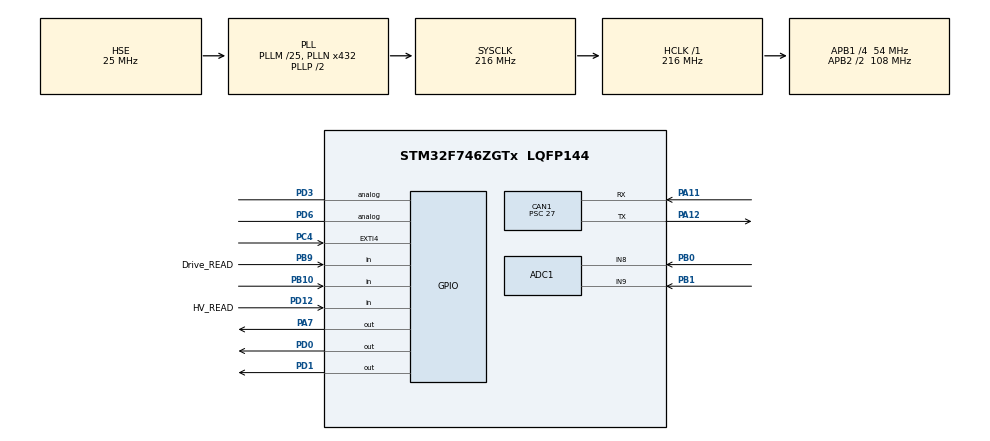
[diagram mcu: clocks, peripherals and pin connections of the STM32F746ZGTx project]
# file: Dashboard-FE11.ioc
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ADC1.Channel-0\#ChannelRegularConversion=ADC_CHANNEL_9
ADC1.NbrOfConversionFlag=1
ADC1.Rank-0\#ChannelRegularConversion=1
ADC1.SamplingTime-0\#ChannelRegularConversion=ADC_SAMPLETIME_3CYCLES
ADC1.master=1
CAN1.BS2=CAN_BS2_2TQ
CAN1.CalculateBaudRate=500000
CAN1.CalculateTimeBit=2000
CAN1.CalculateTimeQuantum=500.0
CAN1.Prescaler=27
Mcu.Family=STM32F7
Mcu.Name=STM32F746ZGTx
Mcu.Package=LQFP144
NVIC.PriorityGroup=NVIC_PRIORITYGROUP_4
PA11.Mode=CAN_Activate
PA11.Signal=CAN1_RX
PA12.Mode=CAN_Activate
PA12.Signal=CAN1_TX
PA7.Signal=GPIO_Output
PB0.Signal=ADCx_IN8
PB1.Signal=ADCx_IN9
PB10.Signal=GPIO_Input
PB11.Signal=USART3_RX
PB9.GPIO_Label=Drive_READ
PB9.Signal=GPIO_Input
PC4.Signal=GPXTI4
PD0.Signal=GPIO_Output
PD1.Signal=GPIO_Output
PD12.GPIO_Label=HV_READ
PD12.GPIO_PuPd=GPIO_PULLDOWN
PD12.Signal=GPIO_Input
PD3.Signal=GPIO_Analog
PD6.Signal=GPIO_Analog
PH0/OSC_IN.Mode=HSE-External-Oscillator
PH0/OSC_IN.Signal=RCC_OSC_IN
PH1/OSC_OUT.Mode=HSE-External-Oscillator
PH1/OSC_OUT.Signal=RCC_OSC_OUT
ProjectManager.HeapSize=0x200
ProjectManager.StackSize=0x400
ProjectManager.TargetToolchain=STM32CubeIDE
RCC.AHBFreq_Value=216000000
RCC.APB1CLKDivider=RCC_HCLK_DIV4
RCC.APB1Freq_Value=54000000
RCC.APB1TimFreq_Value=108000000
RCC.APB2CLKDivider=RCC_HCLK_DIV2
RCC.APB2Freq_Value=108000000
RCC.APB2TimFreq_Value=216000000
RCC.CortexFreq_Value=216000000
RCC.HCLKFreq_Value=216000000
RCC.HSE_VALUE=25000000
RCC.HSI_VALUE=16000000
RCC.LSE_VALUE=32768
RCC.PLLM=25
RCC.PLLN=432
RCC.PLLSourceVirtual=RCC_PLLSOURCE_HSE
RCC.SYSCLKFreq_VALUE=216000000
RCC.SYSCLKSource=RCC_SYSCLKSOURCE_PLLCLK
RCC.USBFreq_Value=216000000
RCC.VCOOutputFreq_Value=432000000
SH.ADCx_IN8.0=ADC1_IN8,IN8
SH.ADCx_IN9.0=ADC1_IN9,IN9
board=custom

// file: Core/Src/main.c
/* USER CODE BEGIN Header */
/**
  ******************************************************************************
  * @file           : main.c
  * @brief          : Main program body
  ******************************************************************************
  * @attention
  *
  * Copyright (c) 2023 STMicroelectronics.
  * All rights reserved.
  *
  * This software is licensed under terms that can be found in the LICENSE file
  * in the root directory of this software component.
  * If no LICENSE file comes with this software, it is provided AS-IS.
  *
  ******************************************************************************
  */
/* USER CODE END Header */
#include "main.h"

/* USER CODE BEGIN Includes */
#include "can_manager.h"
/* USER CODE END Includes */

ADC_HandleTypeDef hadc1;

CAN_HandleTypeDef hcan1;

/* USER CODE BEGIN PV */
uint8_t switches = 0;
uint8_t debugMode = 0;
/* USER CODE END PV */

void SystemClock_Config(void);
static void MX_GPIO_Init(void);
static void MX_CAN1_Init(void);
static void MX_ADC1_Init(void);

int main(void)
{

  /* MCU Configuration--------------------------------------------------------*/

  /* Reset of all peripherals, Initializes the Flash interface and the Systick. */
  HAL_Init();

  /* Configure the system clock */
  SystemClock_Config();

  /* Initialize all configured peripherals */
  MX_GPIO_Init();
  MX_CAN1_Init();
  MX_ADC1_Init();

  /* Infinite loop */
  while (1)
  {
	  // check driver switches
	          if (!HV_Read()) {
	              switches |= 0b10;
	          } else {
	              switches &= 0b11111101;
	          }
	          if (!Drive_Read()) {
	              switches |= 0b1;
	          } else {
	              switches &= 0b11111110;
	          }

	          if (!Digital2_Read()) {
	              if (debugMode) { // switch to drive mode
	                  debugMode = 0;
	              }
	              else { // switch to debug mode
	                  debugMode = 1;
	              }
	          }

	          if (!Digital3_Read() || !Digital4_Read()) {
	              if (switches & 0b100) { // switch to drive mode
	                 switches &= 0b11111011;
	              }
	              else { // switch to debug mode
	                  switches |= 0b100;
	              }
	          }

	          // send driver switches
	          can_send_switches(switches);

	          // this is where we actually display
	          ADC_GLV_V_StartConvert();
	          uint32_t analog_1 = (int32_t)ADC_GLV_V_CountsTo_mVolts(0, ADC_GLV_V_GetResult16(0));
	          torque_limit = analog_1 * 255/3300; // scale to 8 bit

	          //uint32_t glv_v = (int32_t)ADC_GLV_V_CountsTo_mVolts(0, ADC_GLV_V_GetResult16(1));

	          if (debugMode && prev_debugMode == 0){
	              debugTemplate();
	              clear_colors();
	              prev_debugMode = 1;
	          }
	          if (!debugMode && prev_debugMode == 1) {
	              clear_colors();
	              driveTemplate();
	              prev_debugMode = 0;
	          }

	          // big displays are usually 180 by 135
	          // small displays are usually (60-90) by 30
	          // need to adjust size of squares for changing fontSize

	          if(debugMode){
	              disp_SOC(soc, 10, 35, 240, 65, SMALL_FONT);
	              disp_max_pack_temp(PACK_TEMP, 250, 35, 470, 65, SMALL_FONT);
	              disp_state(state, 10, 100, 240, 130, SMALL_FONT);
	              disp_mc_temp(mc_temp, 250, 100, 470, 130, SMALL_FONT);
	              disp_glv_v(0, 10, 165, 240, 195, SMALL_FONT);
	              disp_motor_temp(torque_limit, 250, 165, 470, 195, SMALL_FONT);
	              disp_shutdown_circuit(shutdown_flags, 10, 230, 240, 260, SMALL_FONT);
	              //disp_debug(debug_data, 250, 230, 470, 260, SMALL_FONT);
	              disp_mc_fault(mc_fault_codes, 250, 230, 470, 260, SMALL_FONT);
	          }else{
	              disp_SOC(soc, 30, 35, 210, 170, BIG_FONT);
	              disp_max_pack_temp(PACK_TEMP, 270, 35, 450, 170, BIG_FONT);
	              disp_state(state, 20, 200, 200, 230, SMALL_FONT);
	              disp_glv_v(0, 290, 200, 470, 230, SMALL_FONT);

	          }

	          /*      END display latest data         */

	          if (state == DRIVE && previous_state == HV_ENABLED) {
	              // entered drive; sound ready to drive buzzer

	              Buzzer_Write(1);
	              // EV.10.5.2: Sounded continuously for minimum 1 second
	              // and a maximum of 3 seconds [we use 2 seconds]
	              ReadyToDrive_Timer_Start();

	          }

	          previous_state = state;
	          if (state != DRIVE) {
	              // exited drive
	              Buzzer_Write(0);
	          }

	          RGB3_1_Write(1);
	          RGB2_1_Write(1);
	          RGB1_1_Write(1);

  }
}

void SystemClock_Config(void)
{
  RCC_OscInitTypeDef RCC_OscInitStruct = {0};
  RCC_ClkInitTypeDef RCC_ClkInitStruct = {0};

  /** Configure the main internal regulator output voltage
  */
  __HAL_RCC_PWR_CLK_ENABLE();
  __HAL_PWR_VOLTAGESCALING_CONFIG(PWR_REGULATOR_VOLTAGE_SCALE1);

  /** Initializes the RCC Oscillators according to the specified parameters
  * in the RCC_OscInitTypeDef structure.
  */
  RCC_OscInitStruct.OscillatorType = RCC_OSCILLATORTYPE_HSE;
  RCC_OscInitStruct.HSEState = RCC_HSE_ON;
  RCC_OscInitStruct.PLL.PLLState = RCC_PLL_ON;
  RCC_OscInitStruct.PLL.PLLSource = RCC_PLLSOURCE_HSE;
  RCC_OscInitStruct.PLL.PLLM = 25;
  RCC_OscInitStruct.PLL.PLLN = 432;
  RCC_OscInitStruct.PLL.PLLP = RCC_PLLP_DIV2;
  RCC_OscInitStruct.PLL.PLLQ = 2;
  if (HAL_RCC_OscConfig(&RCC_OscInitStruct) != HAL_OK)
  {
    Error_Handler();
  }

  /** Activate the Over-Drive mode
  */
  if (HAL_PWREx_EnableOverDrive() != HAL_OK)
  {
    Error_Handler();
  }

  /** Initializes the CPU, AHB and APB buses clocks
  */
  RCC_ClkInitStruct.ClockType = RCC_CLOCKTYPE_HCLK|RCC_CLOCKTYPE_SYSCLK
                              |RCC_CLOCKTYPE_PCLK1|RCC_CLOCKTYPE_PCLK2;
  RCC_ClkInitStruct.SYSCLKSource = RCC_SYSCLKSOURCE_PLLCLK;
  RCC_ClkInitStruct.AHBCLKDivider = RCC_SYSCLK_DIV1;
  RCC_ClkInitStruct.APB1CLKDivider = RCC_HCLK_DIV4;
  RCC_ClkInitStruct.APB2CLKDivider = RCC_HCLK_DIV2;

  if (HAL_RCC_ClockConfig(&RCC_ClkInitStruct, FLASH_LATENCY_7) != HAL_OK)
  {
    Error_Handler();
  }
}

static void MX_ADC1_Init(void)
{

  ADC_ChannelConfTypeDef sConfig = {0};

  /** Configure the global features of the ADC (Clock, Resolution, Data Alignment and number of conversion)
  */
  hadc1.Instance = ADC1;
  hadc1.Init.ClockPrescaler = ADC_CLOCK_SYNC_PCLK_DIV4;
  hadc1.Init.Resolution = ADC_RESOLUTION_12B;
  hadc1.Init.ScanConvMode = ADC_SCAN_DISABLE;
  hadc1.Init.ContinuousConvMode = DISABLE;
  hadc1.Init.DiscontinuousConvMode = DISABLE;
  hadc1.Init.ExternalTrigConvEdge = ADC_EXTERNALTRIGCONVEDGE_NONE;
  hadc1.Init.ExternalTrigConv = ADC_SOFTWARE_START;
  hadc1.Init.DataAlign = ADC_DATAALIGN_RIGHT;
  hadc1.Init.NbrOfConversion = 1;
  hadc1.Init.DMAContinuousRequests = DISABLE;
  hadc1.Init.EOCSelection = ADC_EOC_SINGLE_CONV;
  if (HAL_ADC_Init(&hadc1) != HAL_OK)
  {
    Error_Handler();
  }

  /** Configure for the selected ADC regular channel its corresponding rank in the sequencer and its sample time.
  */
  sConfig.Channel = ADC_CHANNEL_9;
  sConfig.Rank = ADC_REGULAR_RANK_1;
  sConfig.SamplingTime = ADC_SAMPLETIME_3CYCLES;
  if (HAL_ADC_ConfigChannel(&hadc1, &sConfig) != HAL_OK)
  {
    Error_Handler();
  }

}

static void MX_CAN1_Init(void)
{

  hcan1.Instance = CAN1;
  hcan1.Init.Prescaler = 27;
  hcan1.Init.Mode = CAN_MODE_NORMAL;
  hcan1.Init.SyncJumpWidth = CAN_SJW_1TQ;
  hcan1.Init.TimeSeg1 = CAN_BS1_1TQ;
  hcan1.Init.TimeSeg2 = CAN_BS2_2TQ;
  hcan1.Init.TimeTriggeredMode = DISABLE;
  hcan1.Init.AutoBusOff = DISABLE;
  hcan1.Init.AutoWakeUp = DISABLE;
  hcan1.Init.AutoRetransmission = DISABLE;
  hcan1.Init.ReceiveFifoLocked = DISABLE;
  hcan1.Init.TransmitFifoPriority = DISABLE;
  if (HAL_CAN_Init(&hcan1) != HAL_OK)
  {
    Error_Handler();
  }

}

static void MX_GPIO_Init(void)
{
  GPIO_InitTypeDef GPIO_InitStruct = {0};

  /* GPIO Ports Clock Enable */
  __HAL_RCC_GPIOH_CLK_ENABLE();
  __HAL_RCC_GPIOA_CLK_ENABLE();
  __HAL_RCC_GPIOC_CLK_ENABLE();
  __HAL_RCC_GPIOB_CLK_ENABLE();
  __HAL_RCC_GPIOD_CLK_ENABLE();

  /*Configure GPIO pin Output Level */
  HAL_GPIO_WritePin(GPIOA, GPIO_PIN_7, GPIO_PIN_RESET);

  /*Configure GPIO pin Output Level */
  HAL_GPIO_WritePin(GPIOD, GPIO_PIN_0|GPIO_PIN_1, GPIO_PIN_RESET);

  /*Configure GPIO pin : PA7 */
  GPIO_InitStruct.Pin = GPIO_PIN_7;
  GPIO_InitStruct.Mode = GPIO_MODE_OUTPUT_PP;
  GPIO_InitStruct.Pull = GPIO_NOPULL;
  GPIO_InitStruct.Speed = GPIO_SPEED_FREQ_LOW;
  HAL_GPIO_Init(GPIOA, &GPIO_InitStruct);

  /*Configure GPIO pin : PC4 */
  GPIO_InitStruct.Pin = GPIO_PIN_4;
  GPIO_InitStruct.Mode = GPIO_MODE_IT_RISING;
  GPIO_InitStruct.Pull = GPIO_NOPULL;
  HAL_GPIO_Init(GPIOC, &GPIO_InitStruct);

  /*Configure GPIO pins : PB10 Drive_READ_Pin */
  GPIO_InitStruct.Pin = GPIO_PIN_10|Drive_READ_Pin;
  GPIO_InitStruct.Mode = GPIO_MODE_INPUT;
  GPIO_InitStruct.Pull = GPIO_NOPULL;
  HAL_GPIO_Init(GPIOB, &GPIO_InitStruct);

  /*Configure GPIO pin : PB11 */
  GPIO_InitStruct.Pin = GPIO_PIN_11;
  GPIO_InitStruct.Mode = GPIO_MODE_AF_PP;
  GPIO_InitStruct.Pull = GPIO_NOPULL;
  GPIO_InitStruct.Speed = GPIO_SPEED_FREQ_VERY_HIGH;
  GPIO_InitStruct.Alternate = GPIO_AF7_USART3;
  HAL_GPIO_Init(GPIOB, &GPIO_InitStruct);

  /*Configure GPIO pin : HV_READ_Pin */
  GPIO_InitStruct.Pin = HV_READ_Pin;
  GPIO_InitStruct.Mode = GPIO_MODE_INPUT;
  GPIO_InitStruct.Pull = GPIO_PULLDOWN;
  HAL_GPIO_Init(HV_READ_GPIO_Port, &GPIO_InitStruct);

  /*Configure GPIO pins : PD0 PD1 */
  GPIO_InitStruct.Pin = GPIO_PIN_0|GPIO_PIN_1;
  GPIO_InitStruct.Mode = GPIO_MODE_OUTPUT_PP;
  GPIO_InitStruct.Pull = GPIO_NOPULL;
  GPIO_InitStruct.Speed = GPIO_SPEED_FREQ_LOW;
  HAL_GPIO_Init(GPIOD, &GPIO_InitStruct);

  /*Configure GPIO pins : PD3 PD6 */
  GPIO_InitStruct.Pin = GPIO_PIN_3|GPIO_PIN_6;
  GPIO_InitStruct.Mode = GPIO_MODE_ANALOG;
  GPIO_InitStruct.Pull = GPIO_NOPULL;
  HAL_GPIO_Init(GPIOD, &GPIO_InitStruct);

}

void Error_Handler(void)
{
  __disable_irq();
  while (1)
  {
  }
}
